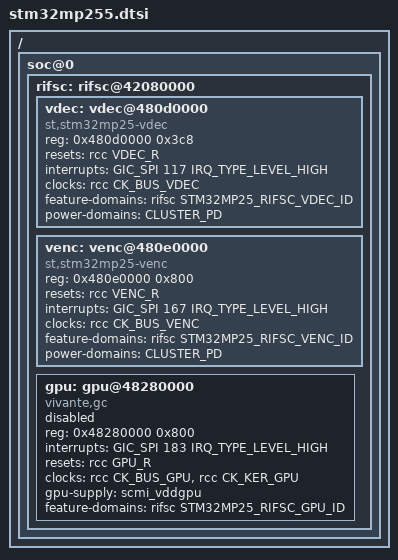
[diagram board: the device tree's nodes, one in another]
// SPDX-License-Identifier: (GPL-2.0-or-later OR BSD-3-Clause)
/*
 * Copyright (C) STMicroelectronics 2023 - All Rights Reserved
 * Author: Alexandre Torgue <alexandre.torgue@foss.st.com> for STMicroelectronics.
 */
#include "stm32mp253.dtsi"

/ {
	soc@0 {
		rifsc: rifsc@42080000 {
			vdec: vdec@480d0000 {
				compatible = "st,stm32mp25-vdec";
				reg = <0x480d0000 0x3c8>;
				resets = <&rcc VDEC_R>;
				interrupt-names = "vdec";
				interrupts = <GIC_SPI 117 IRQ_TYPE_LEVEL_HIGH>;
				clock-names = "vdec-clk";
				clocks = <&rcc CK_BUS_VDEC>;
				feature-domains = <&rifsc STM32MP25_RIFSC_VDEC_ID>;
				power-domains = <&CLUSTER_PD>;
			};
			venc: venc@480e0000 {
				compatible = "st,stm32mp25-venc";
				reg = <0x480e0000 0x800>;
				reset-names = "venc-rst";
				resets = <&rcc VENC_R>;
				interrupt-names = "venc";
				interrupts = <GIC_SPI 167 IRQ_TYPE_LEVEL_HIGH>;
				clock-names = "venc-clk";
				clocks = <&rcc CK_BUS_VENC>;
				feature-domains = <&rifsc STM32MP25_RIFSC_VENC_ID>;
				power-domains = <&CLUSTER_PD>;
			};

			gpu: gpu@48280000 {
				compatible = "vivante,gc";
				reg = <0x48280000 0x800>;
				interrupts = <GIC_SPI 183 IRQ_TYPE_LEVEL_HIGH>;
				resets = <&rcc GPU_R>;
				clock-names = "axi", "core";
				clocks = <&rcc CK_BUS_GPU>, <&rcc CK_KER_GPU>;
				gpu-supply =  <&scmi_vddgpu>;
				feature-domains = <&rifsc STM32MP25_RIFSC_GPU_ID>;
				status = "disabled";
			};
		};
	};
};
